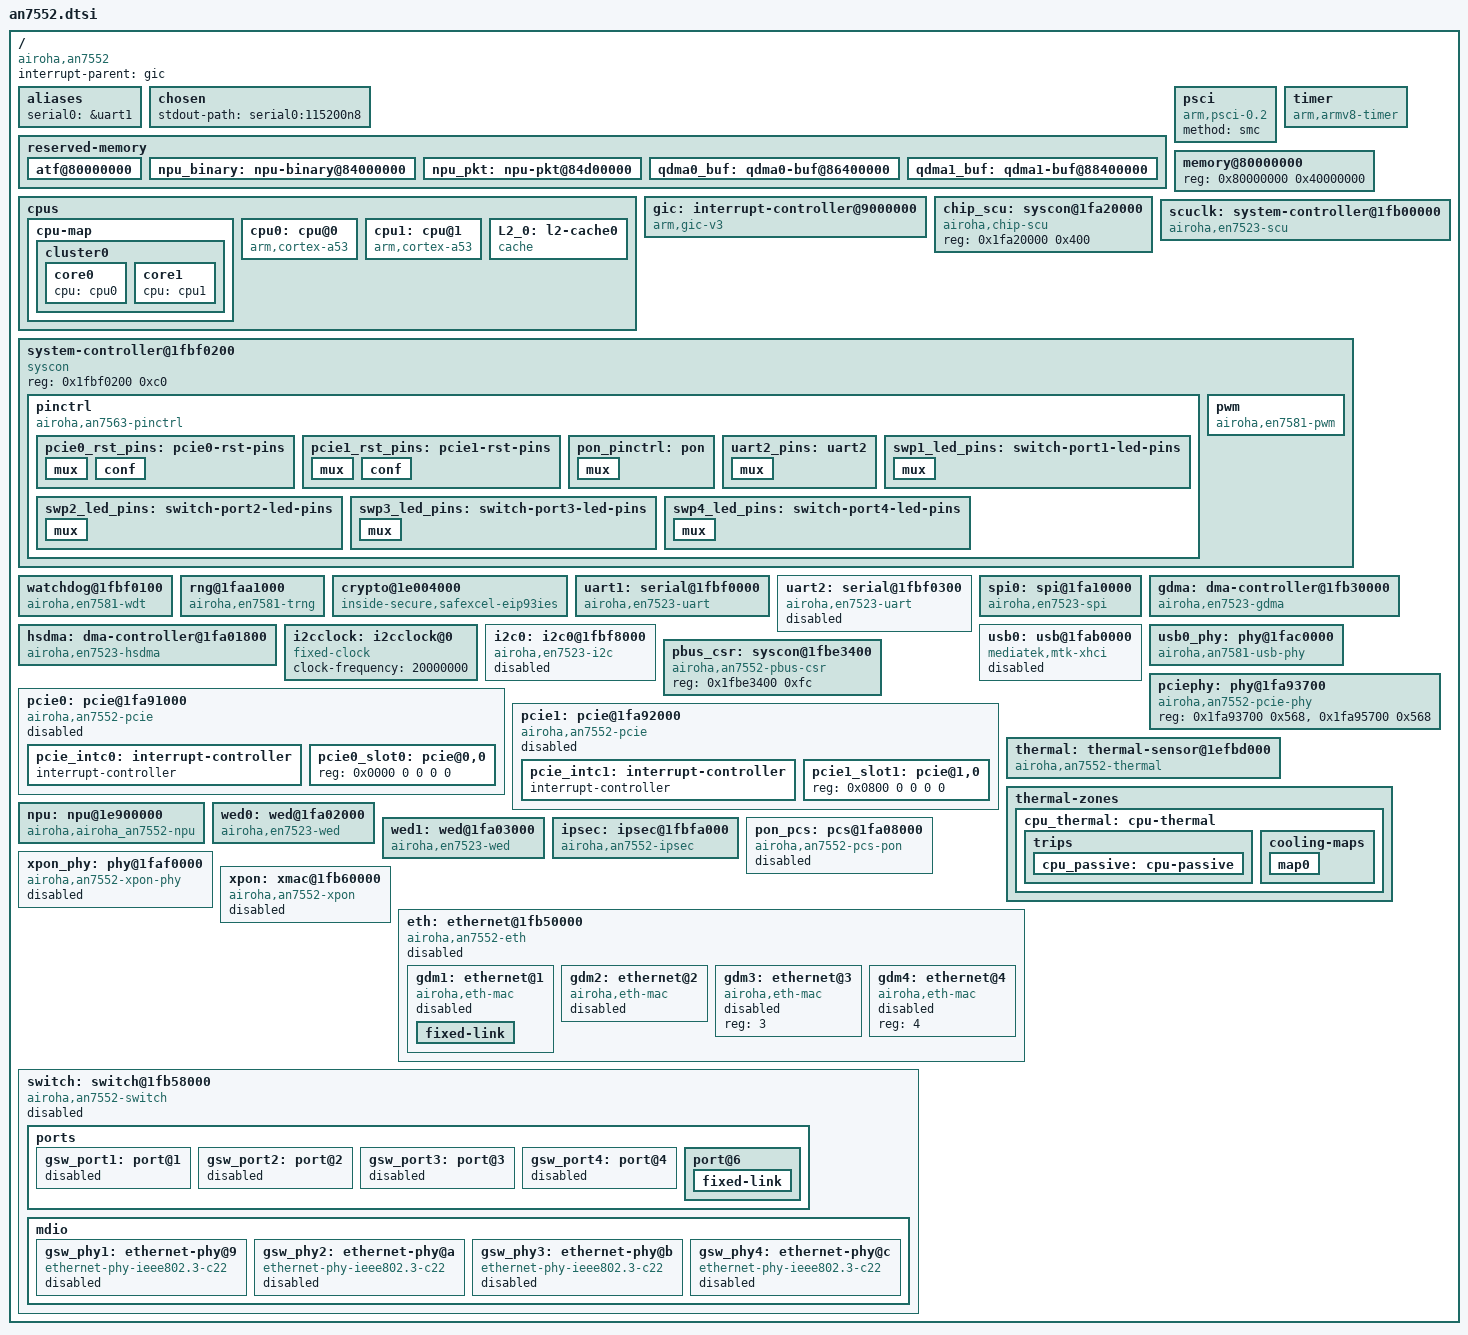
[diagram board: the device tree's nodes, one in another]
// SPDX-License-Identifier: (GPL-2.0-only OR BSD-2-Clause)

#include <dt-bindings/interrupt-controller/irq.h>
#include <dt-bindings/interrupt-controller/arm-gic.h>
#include <dt-bindings/clock/en7523-clk.h>
#include <dt-bindings/reset/airoha,en7523-reset.h>
#include <dt-bindings/leds/common.h>
#include <dt-bindings/gpio/gpio.h>
#include <dt-bindings/soc/airoha,scu-ssr.h>
#include <dt-bindings/thermal/thermal.h>
#include <dt-bindings/phy/phy.h>
#include <dt-bindings/phy/airoha,an7581-usb-phy.h>
#include <dt-bindings/soc/airoha,soc-variant.h>

/ {
	compatible = "airoha,an7552";
	interrupt-parent = <&gic>;
	#address-cells = <1>;
	#size-cells = <1>;

	aliases {
		serial0 = &uart1;
	};

	chosen {
		stdout-path = "serial0:115200n8";
	};

	reserved-memory {
		#address-cells = <1>;
		#size-cells = <1>;
		ranges;

		atf@80000000 {
			no-map;
			reg = <0x80000000 0x40000>;
		};

		npu_binary: npu-binary@84000000 {
			no-map;
			/* Up to 2 MiB of RV32 code, followed by firmware workspace. */
			reg = <0x84000000 0x00400000>;
		};

		npu_pkt: npu-pkt@84d00000 {
			no-map;
			reg = <0x84d00000 0x01600000>;
		};

		qdma0_buf: qdma0-buf@86400000 {
			reg = <0x86400000 0x02000000>;
			no-map;
		};

		qdma1_buf: qdma1-buf@88400000 {
			reg = <0x88400000 0x01000000>;
			no-map;
		};
	};


	cpus {
		#address-cells = <1>;
		#size-cells = <0>;

		cpu-map {
			cluster0 {
				core0 {
					cpu = <&cpu0>;
				};
				core1 {
					cpu = <&cpu1>;
				};
			};
		};

		cpu0: cpu@0 {
			device_type = "cpu";
			compatible = "arm,cortex-a53";
			reg = <0x0>;
			// operating-points-v2 = <&cpu_opp_table>;
			enable-method = "psci";
			clock-frequency = <80000000>;
			next-level-cache = <&L2_0>;
			#cooling-cells = <2>;
		};

		cpu1: cpu@1 {
			device_type = "cpu";
			compatible = "arm,cortex-a53";
			reg = <0x1>;
			// operating-points-v2 = <&cpu_opp_table>;
			enable-method = "psci";
			clock-frequency = <80000000>;
			next-level-cache = <&L2_0>;
			#cooling-cells = <2>;
		};

		L2_0: l2-cache0 {
			compatible = "cache";
		};
	};

	psci {
		compatible = "arm,psci-0.2";
		method = "smc";
	};

	timer {
		compatible = "arm,armv8-timer";
		interrupts = <GIC_PPI 13 IRQ_TYPE_LEVEL_LOW>,
			     <GIC_PPI 14 IRQ_TYPE_LEVEL_LOW>,
			     <GIC_PPI 11 IRQ_TYPE_LEVEL_LOW>,
			     <GIC_PPI 10 IRQ_TYPE_LEVEL_LOW>;
	};

	memory@80000000 {
		device_type = "memory";
		reg = <0x80000000 0x40000000>;
	};

	gic: interrupt-controller@9000000 {
		compatible = "arm,gic-v3";
		reg = <0x09000000 0x20000>,
		      <0x09080000 0x80000>,
		      <0x09400000 0x2000>,
		      <0x09500000 0x2000>,
		      <0x09600000 0x20000>;
		interrupt-controller;
		#interrupt-cells = <3>;
		#address-cells = <0>;
		interrupts = <GIC_PPI 9 IRQ_TYPE_LEVEL_LOW>;
	};

	chip_scu: syscon@1fa20000 {
		compatible = "airoha,chip-scu", "syscon";
		reg = <0x1fa20000 0x400>;
	};

	/* The Ethernet/GSW reset banks retain the EN7523 register layout. */
	scuclk: system-controller@1fb00000 {
		compatible = "airoha,en7523-scu", "airoha,scuclk", "syscon";
		reg = <0x1fb00000 0x1000>, <0x1efbe000 0x800>;
		reg-names = "np-scu", "mcucfg";
		airoha,chip-scu = <&chip_scu>;
		#clock-cells = <1>;
		#reset-cells = <1>;
	};

	system-controller@1fbf0200 {
		compatible = "syscon", "simple-mfd";
		reg = <0x1fbf0200 0xc0>;

		pinctrl: pinctrl {
			compatible = "airoha,an7563-pinctrl";
			interrupts = <GIC_SPI 26 IRQ_TYPE_LEVEL_HIGH>;
			airoha,chip-scu = <&chip_scu>;
			gpio-controller;
			#gpio-cells = <2>;
			gpio-ranges = <&pinctrl 0 0 38>;
			interrupt-controller;
			#interrupt-cells = <2>;
			#address-cells = <0>;

			pcie0_rst_pins: pcie0-rst-pins {
				mux {
					function = "pcie_reset";
					groups = "pcie_reset0";
				};
				conf {
					pins = "pcie_reset0";
					drive-open-drain = <1>;
				};
			};

			pcie1_rst_pins: pcie1-rst-pins {
				mux {
					function = "pcie_reset";
					groups = "pcie_reset1";
				};
				conf {
					pins = "pcie_reset1";
					drive-open-drain = <1>;
				};
			};

			pon_pinctrl: pon {
				mux {
					function = "pon";
					groups = "pon";
				};
			};

			uart2_pins: uart2 {
				mux {
					function = "uart";
					groups = "uart2";
				};
			};

			swp1_led_pins: switch-port1-led-pins {
				mux {
					function = "phy1_led0";
					groups = "gpio8";
				};
			};

			swp2_led_pins: switch-port2-led-pins {
				mux {
					function = "phy2_led0";
					groups = "gpio9";
				};
			};

			swp3_led_pins: switch-port3-led-pins {
				mux {
					function = "phy3_led0";
					groups = "gpio10";
				};
			};

			swp4_led_pins: switch-port4-led-pins {
				mux {
					function = "phy4_led0";
					groups = "gpio11";
				};
			};
		};

		pwm: pwm {
			compatible = "airoha,en7581-pwm";

			#pwm-cells = <3>;
		};
	};

	watchdog@1fbf0100 {
		compatible = "airoha,en7581-wdt";
		reg = <0x1fbf0100 0x40>;

		interrupts = <GIC_SPI 20 IRQ_TYPE_LEVEL_HIGH>,
		             <GIC_SPI 21 IRQ_TYPE_LEVEL_HIGH>,
		             <GIC_SPI 22 IRQ_TYPE_LEVEL_HIGH>,
		             <GIC_SPI 25 IRQ_TYPE_LEVEL_HIGH>;

		clocks = <&scuclk EN7523_CLK_BUS>;
		clock-names = "bus";

		#interrupt-cells = <1>;
	};

	rng@1faa1000 {
		compatible = "airoha,en7581-trng";
		reg = <0x1faa1000 0xc04>;
		interrupts = <GIC_SPI 35 IRQ_TYPE_LEVEL_HIGH>;
	};

	crypto@1e004000 {
		compatible = "inside-secure,safexcel-eip93ies";
		reg = <0x1fb70000 0x1000>;
		interrupts = <GIC_SPI 44 IRQ_TYPE_LEVEL_HIGH>;
	};

	uart1: serial@1fbf0000 {
		compatible = "airoha,en7523-uart";
		reg = <0x1fbf0000 0x30>;
		reg-io-width = <4>;
		reg-shift = <2>;
		clock-frequency = <20000000>;
		interrupts = <GIC_SPI 18 IRQ_TYPE_LEVEL_HIGH>;
	};

	uart2: serial@1fbf0300 {
		compatible = "airoha,en7523-uart";
		reg = <0x1fbf0300 0x30>;
		reg-io-width = <4>;
		reg-shift = <2>;
		clock-frequency = <20000000>;
		interrupts = <GIC_SPI 32 IRQ_TYPE_LEVEL_HIGH>;

		pinctrl-names = "default";
		pinctrl-0 = <&uart2_pins>;

		status = "disabled";
	};

	spi0: spi@1fa10000 {
		compatible = "airoha,en7523-spi";
		reg = <0x1fa10000 0x140>,
		      <0x1fa11000 0x160>;

		interrupts = <GIC_SPI 51 IRQ_TYPE_LEVEL_HIGH>;
		clocks = <&scuclk EN7523_CLK_SPI>;
		clock-names = "spi";

		airoha,scu = <&scuclk>, <&chip_scu>;
		airoha,scu-names = "scuclk", "chip-scu";

		#address-cells = <1>;
		#size-cells = <0>;
	};

	gdma: dma-controller@1fb30000 {
		compatible = "airoha,en7523-gdma";
		reg = <0x1fb30000 0x1000>;

		resets = <&scuclk EN7523_GDMA_RST>;

		#dma-cells = <1>;
		dma-channels = <8>;
	};

	hsdma: dma-controller@1fa01800 {
		compatible = "airoha,en7523-hsdma";
		reg = <0x1fa01800 0x300>;

		resets = <&scuclk EN7523_HSDMA_RST>;
		interrupts = <GIC_SPI 63 IRQ_TYPE_LEVEL_HIGH>;

		#dma-cells = <1>;
		dma-channels = <2>;
	};

	i2cclock: i2cclock@0 {
		#clock-cells = <0>;
		compatible = "fixed-clock";

		/* 20 MHz */
		clock-frequency = <20000000>;
	};

	i2c0: i2c0@1fbf8000 {
		compatible = "airoha,en7523-i2c";
		reg = <0x1fbf8000 0x100>;

		clocks = <&i2cclock>;

		/* 100 kHz */
		clock-frequency = <100000>;
		#address-cells = <1>;
		#size-cells = <0>;

		status = "disabled";
	};

	usb0: usb@1fab0000 {
		compatible = "mediatek,mtk-xhci";
		reg = <0x1fab0000 0x3e00>,
		      <0x1fab3e00 0x100>;
		reg-names = "mac", "ippc";
		interrupts = <GIC_SPI 33 IRQ_TYPE_LEVEL_HIGH>;

		phys = <&usb0_phy PHY_TYPE_USB2>, <&usb0_phy PHY_TYPE_USB3>;

		status = "disabled";
	};

	usb0_phy: phy@1fac0000 {
		compatible = "airoha,an7581-usb-phy";
		reg = <0x1fad0000 0x1fff>;

		airoha,scu = <&scuclk>;
		airoha,usb2-monitor-clk-sel = <AIROHA_USB2_MONCLK_SEL1>;
		airoha,serdes-port = <AIROHA_SCU_SERDES_USB1>;

		#phy-cells = <1>;
	};

	pbus_csr: syscon@1fbe3400 {
		compatible = "airoha,an7552-pbus-csr", "syscon";
		reg = <0x1fbe3400 0xfc>;
	};

	pciephy: phy@1fa93700 {
		compatible = "airoha,an7552-pcie-phy";
		reg = <0x1fa93700 0x568>,
		      <0x1fa95700 0x568>;
		reg-names = "pcie0", "pcie1";
		#phy-cells = <0>;
	};

	pcie0: pcie@1fa91000 {
		compatible = "airoha,an7552-pcie";
		device_type = "pci";
		reg = <0x1fa91000 0x1000>;
		reg-names = "port0";
		linux,pci-domain = <0>;
		#address-cells = <3>;
		#size-cells = <2>;
		interrupts = <GIC_SPI 39 IRQ_TYPE_LEVEL_HIGH>;
		interrupt-names = "pcie_irq";
		clocks = <&scuclk EN7523_CLK_PCIE>;
		clock-names = "sys_ck0";
		bus-range = <0x00 0xff>;
		ranges = <0x82000000 0 0x20000000 0x20000000 0 0x2000000>;
		status = "disabled";

		pinctrl-names = "default";
		pinctrl-0 = <&pcie0_rst_pins>;

		mediatek,pbus-csr = <&pbus_csr 0x0 0x4>;

		phys = <&pciephy>;
		phy-names = "pcie-phy0";

		#interrupt-cells = <1>;
		interrupt-map-mask = <0 0 0 7>;
		interrupt-map = <0 0 0 1 &pcie_intc0 0>,
				<0 0 0 2 &pcie_intc0 1>,
				<0 0 0 3 &pcie_intc0 2>,
				<0 0 0 4 &pcie_intc0 3>;
		pcie_intc0: interrupt-controller {
			interrupt-controller;
			#address-cells = <0>;
			#interrupt-cells = <1>;
		};

		pcie0_slot0: pcie@0,0 {
			reg = <0x0000 0 0 0 0>;
			#address-cells = <3>;
			#size-cells = <2>;
			ranges;
		};
	};

	pcie1: pcie@1fa92000 {
		compatible = "airoha,an7552-pcie";
		device_type = "pci";
		reg = <0x1fa92000 0x1000>;
		reg-names = "port1";
		linux,pci-domain = <1>;
		#address-cells = <3>;
		#size-cells = <2>;
		interrupts = <GIC_SPI 40 IRQ_TYPE_LEVEL_HIGH>;
		interrupt-names = "pcie_irq";
		clocks = <&scuclk EN7523_CLK_PCIE>;
		clock-names = "sys_ck1";
		bus-range = <0x00 0xff>;
		ranges = <0x82000000 0 0x22000000 0x22000000 0 0x2000000>;
		status = "disabled";

		pinctrl-names = "default";
		pinctrl-0 = <&pcie1_rst_pins>;

		mediatek,pbus-csr = <&pbus_csr 0x8 0xc>;

		phys = <&pciephy>;
		phy-names = "pcie-phy1";

		#interrupt-cells = <1>;
		interrupt-map-mask = <0 0 0 7>;
		interrupt-map = <0 0 0 1 &pcie_intc1 0>,
				<0 0 0 2 &pcie_intc1 1>,
				<0 0 0 3 &pcie_intc1 2>,
				<0 0 0 4 &pcie_intc1 3>;
		pcie_intc1: interrupt-controller {
			interrupt-controller;
			#address-cells = <0>;
			#interrupt-cells = <1>;
		};

		pcie1_slot1: pcie@1,0 {
			reg = <0x0800 0 0 0 0>;
			#address-cells = <3>;
			#size-cells = <2>;
			ranges;
		};
	};

	thermal: thermal-sensor@1efbd000 {
		compatible = "airoha,an7552-thermal";
		reg = <0x1efbd000 0x1000>;
		interrupts = <GIC_SPI 23 IRQ_TYPE_LEVEL_HIGH>;
		airoha,chip-scu = <&chip_scu>;

		#thermal-sensor-cells = <0>;
	};

	thermal-zones {
		cpu_thermal: cpu-thermal {
			polling-delay-passive = <200>;
			polling-delay = <1000>;
			thermal-sensors = <&thermal>;
			trips {
				cpu_passive: cpu-passive {
					temperature = <105000>;
					hysteresis = <0>;
					type = "passive";
				};
			};
			cooling-maps {
				map0 {
					trip = <&cpu_passive>;
					cooling-device = <&cpu0 THERMAL_NO_LIMIT THERMAL_NO_LIMIT>,
							 <&cpu1 THERMAL_NO_LIMIT THERMAL_NO_LIMIT>;
				};
			};
		};
	};

	npu: npu@1e900000 {
		compatible = "airoha,airoha_an7552-npu";
		reg = <0x1e900000 0x313000>;
		interrupts = <GIC_SPI 125 IRQ_TYPE_LEVEL_HIGH>,
		             <GIC_SPI 118 IRQ_TYPE_LEVEL_HIGH>,
		             <GIC_SPI 119 IRQ_TYPE_LEVEL_HIGH>,
		             <GIC_SPI 120 IRQ_TYPE_LEVEL_HIGH>,
		             <GIC_SPI 121 IRQ_TYPE_LEVEL_HIGH>,
		             <GIC_SPI 122 IRQ_TYPE_LEVEL_HIGH>,
		             <GIC_SPI 123 IRQ_TYPE_LEVEL_HIGH>,
		             <GIC_SPI 134 IRQ_TYPE_LEVEL_HIGH>,
		             <GIC_SPI 135 IRQ_TYPE_LEVEL_HIGH>;
		interrupt-names = "mbox", "wlan0", "wlan1", "wlan2",
				  "wlan3", "wlan4", "wlan5", "wdt0", "wdt1";

		airoha,scu = <&scuclk>;
		memory-region = <&npu_binary>, <&npu_pkt>;
		memory-region-names = "firmware", "pkt";
	};

	wed0: wed@1fa02000 {
		compatible = "airoha,en7523-wed", "syscon";
		reg = <0x1fa02000 0xb00>,
		      <0x1fa06000 0x400>;
		reg-names = "wed", "wdma";

		interrupts = <GIC_SPI 67 IRQ_TYPE_LEVEL_HIGH>,
		             <GIC_SPI 69 IRQ_TYPE_LEVEL_HIGH>,
		             <GIC_SPI 70 IRQ_TYPE_LEVEL_HIGH>,
		             <GIC_SPI 71 IRQ_TYPE_LEVEL_HIGH>;
		interrupt-names = "wed", "wdma-port0",
		                  "wdma-port1", "wdma-woe";
	};

	wed1: wed@1fa03000 {
		compatible = "airoha,en7523-wed", "syscon";
		reg = <0x1fa03000 0xb00>,
		      <0x1fa06400 0x400>;
		reg-names = "wed", "wdma";

		interrupts = <GIC_SPI 68 IRQ_TYPE_LEVEL_HIGH>,
		             <GIC_SPI 72 IRQ_TYPE_LEVEL_HIGH>,
		             <GIC_SPI 73 IRQ_TYPE_LEVEL_HIGH>,
		             <GIC_SPI 74 IRQ_TYPE_LEVEL_HIGH>;
		interrupt-names = "wed", "wdma-port0",
		                  "wdma-port1", "wdma-woe";
	};

	ipsec: ipsec@1fbfa000 {
		compatible = "airoha,an7552-ipsec";
		reg = <0x1fbfa000 0x268>;

		interrupts = <GIC_SPI 79 IRQ_TYPE_LEVEL_HIGH>;
	};

	pon_pcs: pcs@1fa08000 {
		compatible = "airoha,an7552-pcs-pon";
		reg = <0x1fa08000 0x1000>,
		      <0x1fa80000 0x64>,
		      <0x1fa80a00 0x168>,
		      <0x1fa84000 0x1000>,
		      <0x1fa86000 0x400>,
		      <0x1faf3000 0x1000>,
		      <0x1faf4000 0x1000>;
		reg-names = "pcs_mac", "hsgmii_an", "hsgmii_pcs",
			    "multi_sgmii", "hsgmii_rate_adp",
			    "pcs_ana", "pcs_pma";

		resets = <&scuclk EN7523_XPON_MAC_RST>,
			 <&scuclk EN7523_XPON_PHY_RST>;
		reset-names = "mac", "phy";

		airoha,scu = <&scuclk>;

		#pcs-cells = <0>;

		status = "disabled";
	};

	xpon_phy: phy@1faf0000 {
		compatible = "airoha,an7552-xpon-phy";
		reg = <0x1faf0000 0x5000>;

		pinctrl-names = "default";
		pinctrl-0 = <&pon_pinctrl>;

		interrupts = <GIC_SPI 43 IRQ_TYPE_LEVEL_HIGH>;
		resets = <&scuclk EN7523_XPON_PHY_RST>;
		reset-names = "phy";

		airoha,scu = <&scuclk>;
		airoha,chip-scu = <&chip_scu>;
		tx-disable-gpios = <&pinctrl 14 GPIO_ACTIVE_HIGH>;

		#phy-cells = <0>;

		status = "disabled";
	};

	xpon: xmac@1fb60000 {
		compatible = "airoha,an7552-xpon";

		reg = <0x1fb60000 0x10000>;
		reg-names = "mac";

		interrupts = <GIC_SPI 42 IRQ_TYPE_LEVEL_HIGH>,
		             <GIC_SPI 34 IRQ_TYPE_LEVEL_HIGH>;
		interrupt-names = "mac", "dying-gasp";

		resets = <&scuclk EN7523_XPON_MAC_RST>;
		reset-names = "mac";

		phys = <&xpon_phy>;
		phy-names = "xpon";

		ethernet = <&gdm2>;
		airoha,scu = <&scuclk>;

		status = "disabled";
	};

	eth: ethernet@1fb50000 {
		compatible = "airoha,an7552-eth";
		status = "disabled";
		reg = <0x1fb50000 0x2600>,
		      <0x1fb54000 0x2000>,
		      <0x1fb56000 0x2000>,
		      <0x1fbf9000 0x1000>;
		reg-names = "fe", "qdma0", "qdma1", "gdmp";

		resets = <&scuclk EN7523_FE_RST>,
			 <&scuclk EN7523_FE_PDMA_RST>,
			 <&scuclk EN7523_FE_QDMA_RST>,
			 <&scuclk EN7523_GDMP_RST>,
			 <&scuclk EN7523_TDMA_RST>;
		reset-names = "fe", "pdma", "qdma",
			      "gdmp", "tdma";

		interrupts = <GIC_SPI 37 IRQ_TYPE_LEVEL_HIGH>,
			     <GIC_SPI 55 IRQ_TYPE_LEVEL_HIGH>,
			     <GIC_SPI 56 IRQ_TYPE_LEVEL_HIGH>,
			     <GIC_SPI 57 IRQ_TYPE_LEVEL_HIGH>,
			     <GIC_SPI 38 IRQ_TYPE_LEVEL_HIGH>,
			     <GIC_SPI 58 IRQ_TYPE_LEVEL_HIGH>,
			     <GIC_SPI 59 IRQ_TYPE_LEVEL_HIGH>,
			     <GIC_SPI 60 IRQ_TYPE_LEVEL_HIGH>,
			     <GIC_SPI 49 IRQ_TYPE_LEVEL_HIGH>,
			     <GIC_SPI 64 IRQ_TYPE_LEVEL_HIGH>;
		interrupt-names = "lan0", "lan1", "lan2", "lan3",
				  "wan0", "wan1", "wan2", "wan3",
				  "fe-error", "pdma";

		memory-region = <&qdma0_buf>, <&qdma1_buf>;
		memory-region-names = "qdma0-buf", "qdma1-buf";

		airoha,npu = <&npu>;
		airoha,wed = <&wed0>, <&wed1>;

		#address-cells = <1>;
		#size-cells = <0>;

		gdm1: ethernet@1 {
			compatible = "airoha,eth-mac";
			reg = <1>;
			phy-mode = "internal";
			status = "disabled";

			fixed-link {
				speed = <10000>;
				full-duplex;
				pause;
			};
		};

		gdm2: ethernet@2 {
			compatible = "airoha,eth-mac";
			reg = <2>;
			pcs-handle = <&pon_pcs>;

			status = "disabled";
		};

		gdm3: ethernet@3 {
			compatible = "airoha,eth-mac";
			reg = <3>;

			status = "disabled";
		};

		gdm4: ethernet@4 {
			compatible = "airoha,eth-mac";
			reg = <4>;

			status = "disabled";
		};
	};

	switch: switch@1fb58000 {
		compatible = "airoha,an7552-switch";
		reg = <0x1fb58000 0x8000>;
		resets = <&scuclk EN7523_GSW_RST>;
		interrupts = <GIC_SPI 31 IRQ_TYPE_LEVEL_HIGH>;
		interrupt-controller;
		#interrupt-cells = <1>;
		#address-cells = <0>;
		status = "disabled";

		ports {
			#address-cells = <1>;
			#size-cells = <0>;

			gsw_port1: port@1 {
				reg = <1>;
				phy-mode = "internal";
				phy-handle = <&gsw_phy1>;
				status = "disabled";
			};

			gsw_port2: port@2 {
				reg = <2>;
				phy-mode = "internal";
				phy-handle = <&gsw_phy2>;
				status = "disabled";
			};

			gsw_port3: port@3 {
				reg = <3>;
				phy-mode = "internal";
				phy-handle = <&gsw_phy3>;
				status = "disabled";
			};

			gsw_port4: port@4 {
				reg = <4>;
				phy-mode = "internal";
				phy-handle = <&gsw_phy4>;
				status = "disabled";
			};

			port@6 {
				reg = <6>;
				ethernet = <&gdm1>;
				phy-mode = "internal";

				fixed-link {
					speed = <10000>;
					full-duplex;
					pause;
				};
			};
		};

		mdio: mdio {
			#address-cells = <1>;
			#size-cells = <0>;

			gsw_phy1: ethernet-phy@9 {
				compatible = "ethernet-phy-ieee802.3-c22";
				reg = <9>;
				airoha,mdi-resistor-ohms = <5>;
				status = "disabled";
			};

			gsw_phy2: ethernet-phy@a {
				compatible = "ethernet-phy-ieee802.3-c22";
				reg = <10>;
				airoha,mdi-resistor-ohms = <5>;
				status = "disabled";
			};

			gsw_phy3: ethernet-phy@b {
				compatible = "ethernet-phy-ieee802.3-c22";
				reg = <11>;
				airoha,mdi-resistor-ohms = <5>;
				status = "disabled";
			};

			gsw_phy4: ethernet-phy@c {
				compatible = "ethernet-phy-ieee802.3-c22";
				reg = <12>;
				airoha,mdi-resistor-ohms = <5>;
				status = "disabled";
			};
		};
	};
};
